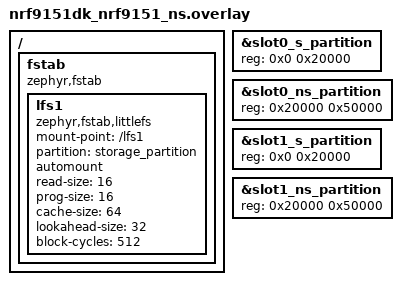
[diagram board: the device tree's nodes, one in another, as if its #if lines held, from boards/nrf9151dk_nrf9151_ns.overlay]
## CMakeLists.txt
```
# SPDX-License-Identifier: Apache-2.0

cmake_minimum_required(VERSION 3.13.1)

if(DEFINED ENV{MEMFAULT_ZEPHYR_EXTRA_MODULE_INCLUDE})
  list(APPEND ZEPHYR_EXTRA_MODULES $ENV{ZEPHYR_BASE}/../modules/memfault-firmware-sdk/ports)
endif()

# We need the nRF Connect SDK version before loading Zephyr, to dynamically
# select Kconfig overlays based on version- not something that can be achieved
# with Zephyr today.
#
# Note: previously this was done with 'find_package(Ncs)', but as of sdk-nrf
# commit 40f7487d3a ("cmake: adopt VERSION to common VERSION file format"),
# NcsConfig.cmake requires ZEPHYR_BASE to be set, which is not available before
# 'find_package(Zephyr)'. Instead, read the version directly from the VERSION
# file, supporting both formats:
# - nRF Connect SDK <= v3.3.0: single line, "<major>.<minor>.<patch>[-extra]"
# - newer: Zephyr-style "VERSION_MAJOR = <major>" etc. key-value lines
set(NCS_VERSION_FILE "$ENV{ZEPHYR_BASE}/../nrf/VERSION")
if(EXISTS "${NCS_VERSION_FILE}")
  file(READ "${NCS_VERSION_FILE}" ncs_version_content)
  if(ncs_version_content MATCHES "VERSION_MAJOR *= *([0-9]+)")
    set(NCS_VERSION_MAJOR ${CMAKE_MATCH_1})
    string(REGEX MATCH "VERSION_MINOR *= *([0-9]+)" _ "${ncs_version_content}")
    set(NCS_VERSION_MINOR ${CMAKE_MATCH_1})
    string(REGEX MATCH "PATCHLEVEL *= *([0-9]+)" _ "${ncs_version_content}")
    set(NCS_VERSION_PATCH ${CMAKE_MATCH_1})
  elseif(ncs_version_content MATCHES "([0-9]+)\\.([0-9]+)\\.([0-9]+)")
    set(NCS_VERSION_MAJOR ${CMAKE_MATCH_1})
    set(NCS_VERSION_MINOR ${CMAKE_MATCH_2})
    set(NCS_VERSION_PATCH ${CMAKE_MATCH_3})
  endif()
endif()

# Confirm NCS_VERSION_MAJOR is defined
if (NOT DEFINED NCS_VERSION_MAJOR)
  message(FATAL_ERROR "NCS Version not found, please contact Memfault support!")
endif()

# Below we conditionally set Kconfig variables via overlays based on nRF Connect SDK version
# (since setting non-existent variables result in a build time error which
# would break compiling older builds)

if (${NCS_VERSION_MAJOR}.${NCS_VERSION_MINOR}.${NCS_VERSION_PATCH} VERSION_GREATER_EQUAL 2.9.99)
set(OVERLAY_CONFIG "${OVERLAY_CONFIG};overlays/ncs-main.conf")
endif()

if (${NCS_VERSION_MAJOR}.${NCS_VERSION_MINOR}.${NCS_VERSION_PATCH} VERSION_GREATER_EQUAL 3.3.0)
set(OVERLAY_CONFIG "${OVERLAY_CONFIG};overlays/ncs-v3.3.0.conf")
endif()

if (${NCS_VERSION_MAJOR}.${NCS_VERSION_MINOR}.${NCS_VERSION_PATCH} VERSION_LESS 2.9.99)
set(OVERLAY_CONFIG "${OVERLAY_CONFIG};overlays/ncs-pre-v2.9.99.conf")
endif()

if (${NCS_VERSION_MAJOR}.${NCS_VERSION_MINOR}.${NCS_VERSION_PATCH} VERSION_LESS 2.8.0)
set(OVERLAY_CONFIG "${OVERLAY_CONFIG};overlays/ncs-pre-v2.8.0.conf")
endif()

if (${NCS_VERSION_MAJOR}.${NCS_VERSION_MINOR}.${NCS_VERSION_PATCH} VERSION_LESS 2.2.99)
set(OVERLAY_CONFIG "${OVERLAY_CONFIG};overlays/ncs-pre-v2.2.99.conf")
endif()

if (${NCS_VERSION_MAJOR}.${NCS_VERSION_MINOR}.${NCS_VERSION_PATCH} VERSION_LESS 2.4.0)
set(OVERLAY_CONFIG "${OVERLAY_CONFIG};overlays/ncs-pre-v2.4.0.conf")
endif()

if (${NCS_VERSION_MAJOR}.${NCS_VERSION_MINOR}.${NCS_VERSION_PATCH} VERSION_LESS 2.0.0)
set(OVERLAY_CONFIG "${OVERLAY_CONFIG};overlays/ncs-pre-v2.0.0.conf")
endif()

# NCS >= 3.4.0 disables Partition Manager by default, which changes the
# secure/non-secure flash split on nRF91-family DK boards (see the
# NCS_PARTITION_MANAGER_REMOVED guarded blocks in boards/*.overlay for
# details). BOARD isn't known yet at this point in a sysbuild configure, so
# this can't be gated by board here - instead it's passed down as a
# devicetree preprocessor define, and the affected board overlay files guard
# their partition-resizing nodes on it.
if (${NCS_VERSION_MAJOR}.${NCS_VERSION_MINOR}.${NCS_VERSION_PATCH} VERSION_GREATER_EQUAL 3.4.0)
set(DTS_EXTRA_CPPFLAGS "${DTS_EXTRA_CPPFLAGS};-DNCS_PARTITION_MANAGER_REMOVED")
endif()

find_package(Zephyr HINTS $ENV{ZEPHYR_BASE})
project(hello_world)

target_sources(app PRIVATE src/main.c)
target_sources(app PRIVATE src/watchdog.c)
zephyr_include_directories(config)
```

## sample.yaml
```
sample:
  description: Memfault SDK example integration built on top of Hello
    World Sample App with the nRF Connect SDK
  name: Memfault Demo App
```

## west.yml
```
manifest:
  projects:
    - name: nrf
      url: https://github.com/nrfconnect/sdk-nrf
      revision: v3.4.1
      import:
        path-blocklist: modules/lib/memfault-firmware-sdk
        name-blocklist:
          # unused, save the download
          - matter
    - name: memfault-firmware-sdk
      url: https://github.com/memfault/memfault-firmware-sdk
      path: modules/lib/memfault-firmware-sdk
      revision: master
  self:
    path: memfault_demo_app
    import: submanifests
```

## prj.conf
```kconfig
# project specific configuration settings

# Note: See the overlays directory for additional Kconfig variables settings as not all variables can be
# set in a single prj.conf for backward compatibility with older versions of the nRF Connect SDK /
# Zephyr

CONFIG_NETWORKING=y
CONFIG_NET_SOCKETS=y
CONFIG_NET_NATIVE=n

CONFIG_HEAP_MEM_POOL_SIZE=4096
CONFIG_MAIN_STACK_SIZE=4096
CONFIG_SYSTEM_WORKQUEUE_STACK_SIZE=2048
CONFIG_MODEM_KEY_MGMT=y
CONFIG_LTE_LINK_CONTROL=y
CONFIG_NRF_MODEM_LIB=y
CONFIG_MODEM_INFO=y
CONFIG_AT_SHELL=y
# Note: CONFIG_AT_SHELL_CMD_MODE is set in overlays/ncs-v3.3.0.conf for NCS >= 3.3.0

CONFIG_SHELL=y
CONFIG_SHELL_LOG_BACKEND=n

# Make it possible to send AT commands ending with a "?"
#  https://developer.nordicsemi.com/nRF_Connect_SDK/doc/2.4.2/nrf/libraries/modem/at_shell.html
CONFIG_SHELL_WILDCARD=y

CONFIG_NET_LOG=y

CONFIG_NET_SOCKETS_OFFLOAD=y

CONFIG_MEMFAULT=y
CONFIG_MEMFAULT_NCS_DEVICE_ID_RUNTIME=y

# Note: Can optionally be changed to =y to implement
# a custom event handler for FOTA events
# CONFIG_MEMFAULT_FOTA_DOWNLOAD_CALLBACK_CUSTOM=n

# Enable to demo custom reboot reason capture
CONFIG_MEMFAULT_REBOOT_REASON_CUSTOM_ENABLE=y

# Required for logging backends to work as expected
CONFIG_LOG=y
CONFIG_LOG_BACKEND_UART=y

# Disable logging of printk, to improve 'mflt export' performance under deferred
# logging mode.
CONFIG_LOG_PRINTK=n

# Enable Bootloader so OTA updates can be performed
CONFIG_BOOTLOADER_MCUBOOT=y
CONFIG_MCUBOOT_IMG_MANAGER=y

# The subsystems we need so OTA payloads can be written to
# flash and updated by MCUBoot
CONFIG_DFU_TARGET=y
CONFIG_DFU_TARGET_MCUBOOT=y
CONFIG_IMG_MANAGER=y
CONFIG_FLASH=y
CONFIG_FLASH_MAP=y
CONFIG_STREAM_FLASH=y
CONFIG_IMG_ERASE_PROGRESSIVELY=y

# For Memfault FOTA, we will use the FOTA_DOWNLOAD API's
# from the nRF Connect SDK which depends on the DOWNLOAD_CLIENT
CONFIG_FOTA_DOWNLOAD=y

# Enable Modem FOTA via Memfault
# CONFIG_MEMFAULT_FOTA_MODEM_UPDATE=y
# Optional, only if modem firmware is hosted in a separate, dedicated project:
# CONFIG_MEMFAULT_FOTA_MODEM_PROJECT_KEY="fill_in_modem_fota_project_key"

# Enable printing of file download progress to console
CONFIG_FOTA_DOWNLOAD_PROGRESS_EVT=y

CONFIG_WATCHDOG=y

# Enable Zephyr runtime asserts
CONFIG_ASSERT=y

# Enable littlefs on internal flash, to demo the file system utilization metric
CONFIG_FILE_SYSTEM=y
CONFIG_FILE_SYSTEM_LITTLEFS=y
CONFIG_FILE_SYSTEM_SHELL=y

# Enable Nordic datetime library, which will get network time from the modem
CONFIG_DATE_TIME=y
```

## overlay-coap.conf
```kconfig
# Overlay for selecting CoAP for connecting to Memfault.
# Requires NCS >=2.8.0.

# Enable CoAP, disable HTTP
CONFIG_MEMFAULT_USE_NRF_CLOUD_COAP=y
CONFIG_MEMFAULT_HTTP_ENABLE=n

# Enable Modem FOTA updates
# Uses the main project by default. To use a separate, dedicated modem project, set its key via
# CLI (mflt set_modem_project_key) or via Kconfig (CONFIG_MEMFAULT_FOTA_MODEM_PROJECT_KEY)
CONFIG_MEMFAULT_FOTA_MODEM_UPDATE=y

# nRF Cloud CoAP (required for Memfault CoAP uploads)
CONFIG_NRF_CLOUD=y
CONFIG_NRF_CLOUD_COAP=y
# Use the modem's internal UUID as the nRF Cloud client ID (for JWT auth)
CONFIG_NRF_CLOUD_CLIENT_ID_SRC_INTERNAL_UUID=y
CONFIG_MODEM_JWT=y

# Required to be able to use the nRF Cloud CoAP connection for FOTA image downloads
CONFIG_NRF_CLOUD_FOTA=y
CONFIG_DOWNLOADER_TRANSPORT_COAP=y

# Ensure Memfault device id matches nRF Cloud client id
CONFIG_MEMFAULT_NCS_DEVICE_ID_HW_ID=y
CONFIG_HW_ID_LIBRARY_SOURCE_UUID=y

# CoAP client (needs more stack and heap than HTTP)
CONFIG_COAP_CLIENT_BLOCK_SIZE=1024
CONFIG_COAP_CLIENT_STACK_SIZE=6144
CONFIG_COAP_CLIENT_THREAD_PRIORITY=0
CONFIG_COAP_CLIENT_MAX_PATH_LENGTH=400
CONFIG_AT_MONITOR_HEAP_SIZE=512
CONFIG_SHELL_STACK_SIZE=2560

# Required for streaming large FOTA images from nRF Cloud over CoAP
CONFIG_HEAP_MEM_POOL_SIZE=12288

CONFIG_COAP_EXTENDED_OPTIONS_LEN_VALUE=192
CONFIG_NRF_CLOUD_COAP_MAX_USER_OPTIONS=2
CONFIG_COAP_CLIENT_MAX_EXTRA_OPTIONS=3

# nRF Cloud shadow updates use cJSON which serializes float/double values via
# snprintf("%g", ...). Without this, floats render as "*float*" in the JSON
# string, causing nRF Cloud to reject shadow PATCHes with "Malformed JSON".
CONFIG_CBPRINTF_FP_SUPPORT=y
```

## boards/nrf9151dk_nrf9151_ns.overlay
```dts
/* Device Tree overlay to enable auto-mounting littlefs in an internal
   partition, via the Nordic Partition Manager system */

/ {
	fstab {
		compatible = "zephyr,fstab";
		lfs1: lfs1 {
			compatible = "zephyr,fstab,littlefs";
			mount-point = "/lfs1";
			partition = <&storage_partition>;
			automount;
			read-size = <16>;
			prog-size = <16>;
			cache-size = <64>;
			lookahead-size = <32>;
			block-cycles = <512>;
		};
	};
};

#if defined(NCS_PARTITION_MANAGER_REMOVED)
/*
 * NCS >= 3.4.0 disables Partition Manager by default, falling back to this
 * board's static devicetree partition layout, which splits the primary and
 * secondary image areas into a 256 KB secure (TF-M) / 192 KB non-secure
 * region. When Partition Manager was in control it sized that split
 * dynamically based on what TF-M and this app actually needed.
 * For the non-secure image, it chose 320 KB, which gives it plenty of headroom. Shrink the secure region
 * and grow the non-secure one to match what Partition Manager used to
 * allocate, so the app still fits.
 */
&slot0_s_partition {
	reg = <0x0 0x20000>;
};

&slot0_ns_partition {
	reg = <0x20000 0x50000>;
};

&slot1_s_partition {
	reg = <0x0 0x20000>;
};

&slot1_ns_partition {
	reg = <0x20000 0x50000>;
};
#endif
```

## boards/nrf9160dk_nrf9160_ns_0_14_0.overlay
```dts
/* Device Tree overlay to enable auto-mounting littlefs in an internal
   partition, via the Nordic Partition Manager system */

/ {
	fstab {
		compatible = "zephyr,fstab";
		lfs1: lfs1 {
			compatible = "zephyr,fstab,littlefs";
			mount-point = "/lfs1";
			partition = <&storage_partition>;
			automount;
			read-size = <16>;
			prog-size = <16>;
			cache-size = <64>;
			lookahead-size = <32>;
			block-cycles = <512>;
		};
	};
};

#if defined(NCS_PARTITION_MANAGER_REMOVED)
/*
 * NCS >= 3.4.0 disables Partition Manager by default, falling back to this
 * board's static devicetree partition layout, which splits the primary and
 * secondary image areas into a 256 KB secure (TF-M) / 192 KB non-secure
 * region. When Partition Manager was in control it sized that split
 * dynamically based on what TF-M and this app actually needed, leaving this
 * app's non-secure image comfortably under 320 KB. Shrink the secure region
 * and grow the non-secure one to match what Partition Manager used to
 * allocate, so the app still fits.
 */
&slot0_s_partition {
	reg = <0x0 0x20000>;
};

&slot0_ns_partition {
	reg = <0x20000 0x50000>;
};

&slot1_s_partition {
	reg = <0x0 0x20000>;
};

&slot1_ns_partition {
	reg = <0x20000 0x50000>;
};
#endif
```

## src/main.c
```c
//! @file
//!
//! Copyright (c) Memfault, Inc.
//! See LICENSE for details

// clang-format off
#include "memfault/ports/zephyr/include_compatibility.h"

#include MEMFAULT_ZEPHYR_INCLUDE(device.h)
#include MEMFAULT_ZEPHYR_INCLUDE(kernel.h)
#include MEMFAULT_ZEPHYR_INCLUDE(sys/printk.h)
#include MEMFAULT_ZEPHYR_INCLUDE(shell/shell.h)
#include <string.h>
#include <stdio.h>

#include "memfault/components.h"
#include "memfault/ports/zephyr/thread_metrics.h"
#include "memfault/ports/zephyr/http.h"
#include "memfault/ports/ncs/version.h"
#include "memfault/ports/ncs/date_time_callback.h"
#include "memfault_demo_app.h"

#if defined(CONFIG_AT_SHELL_CMD_MODE)
#include <modem/at_shell.h>
#endif

#include <modem/modem_info.h>
#ifdef CONFIG_LTE_LINK_CONTROL
  #include <modem/lte_lc.h>
#else
  #include <nrf_modem_at.h>
#endif

#if defined(CONFIG_NRF_CLOUD_COAP)
#include <date_time.h>
#include <net/nrf_cloud_coap.h>

static K_SEM_DEFINE(s_date_time_ready, 0, 1);

static void prv_date_time_evt_handler(const struct date_time_evt *evt) {
#if defined(CONFIG_MEMFAULT_SYSTEM_TIME_SOURCE_DATETIME)
  // Forward event to Memfault's date/time callback handler, which will update
  // the system time used for timestamping events and coredumps
  memfault_zephyr_date_time_evt_handler(evt);
#endif

  // Only signal that date/time is ready on successful time obtain events
  if ((evt != NULL) && (evt->type != DATE_TIME_NOT_OBTAINED)) {
    k_sem_give(&s_date_time_ready);
  }
}
#endif

MEMFAULT_METRICS_DEFINE_THREAD_METRICS(
{
  .thread_name = "idle",
  .stack_usage_metric_key = MEMFAULT_METRICS_KEY(memory_idle_pct_max),
},
{
  .thread_name = "sysworkq",
  .stack_usage_metric_key = MEMFAULT_METRICS_KEY(memory_sysworkq_pct_max),
},
{
  .thread_name = "mflt_upload",
  .stack_usage_metric_key = MEMFAULT_METRICS_KEY(memory_mflt_upload_pct_max),
},
{
  .thread_name = "🐶 wdt",
  .stack_usage_metric_key = MEMFAULT_METRICS_KEY(memory_wdt_pct_max),
},
{
  .thread_name = "shell_uart",
  .stack_usage_metric_key = MEMFAULT_METRICS_KEY(memory_shell_uart_pct_max),
}
);

#if !MEMFAULT_NCS_VERSION_GT(2, 3)
/* nRF Connect SDK >= 1.9.2 || <= 2.3 */
#include "memfault_ncs.h"
#include <modem/nrf_modem_lib.h>
static int prv_init_modem_lib(void) {
  return nrf_modem_lib_init(NORMAL_MODE);
}
#else /* nRF Connect SDK >= 2.4 */
#include "memfault_ncs.h"
#include <modem/nrf_modem_lib.h>
static int prv_init_modem_lib(void) {
  return nrf_modem_lib_init();
}
#endif

#include MEMFAULT_ZEPHYR_INCLUDE(logging/log.h)
LOG_MODULE_REGISTER(mflt_demo_app, LOG_LEVEL_INF);

#if CONFIG_DFU_TARGET_MCUBOOT
#include MEMFAULT_ZEPHYR_INCLUDE(dfu/mcuboot.h)
#endif

#if defined(CONFIG_MEMFAULT_FOTA_COMPONENTS)
#include "memfault/nrfconnect_port/fota_component.h"
#endif
// clang-format on

#if defined(CONFIG_MEMFAULT_FOTA_COMPONENTS)
// Phony component for testing, e.g. with "mflt get_latest_url example-component"
static int prv_example_component_version_get(char *buf, size_t buf_len) {
  snprintf(buf, buf_len, "1.0.0");
  return 0;
}

MEMFAULT_FOTA_COMPONENT_DEFINE(example_component, "example-component",
                               prv_example_component_version_get,
                               kMemfaultFotaComponentInstall_None);
#endif

#if defined(CONFIG_MEMFAULT_NCS_DEVICE_ID_RUNTIME)
  // Since the example app manages when the modem starts/stops, we manually configure the device
  // serial even when using nRF Connect SDKs including the Memfault integration (by using
  // CONFIG_MEMFAULT_NCS_DEVICE_ID_RUNTIME)
  #define IMEI_LEN 15
static char s_device_serial[IMEI_LEN + 1 /* '\0' */] = "unknown";

static int prv_get_imei(char *buf, size_t buf_len) {
  // use the cached modem info to fetch the IMEI
  int err = modem_info_init();
  if (err != 0) {
    printk("Modem info Init error: %d\n", err);
  } else {
    modem_info_string_get(MODEM_INFO_IMEI, buf, buf_len);
  }
  return err;
}

static void prv_init_device_info(void) {
  // we'll use the IMEI as the device serial
  char modem_info[MODEM_INFO_MAX_RESPONSE_SIZE];

  int ret = prv_get_imei(modem_info, sizeof(modem_info));
  if (ret != 0) {
    printk("Failed to get IMEI\n\r");
  } else {
    modem_info[IMEI_LEN] = '\0';
    strcpy(s_device_serial, modem_info);
    printk("IMEI: %s\n", s_device_serial);
  }

  // register the device id with memfault port so it is used for reporting
  memfault_ncs_device_id_set(s_device_serial, IMEI_LEN);
}
#endif

#if defined(CONFIG_AT_SHELL_CMD_MODE)
K_THREAD_STACK_DEFINE(my_work_q_stack, 2048);
static struct k_work_q my_work_q;

static void prv_at_shell_init(void) {
  k_work_queue_start(&my_work_q, my_work_q_stack, K_THREAD_STACK_SIZEOF(my_work_q_stack),
                     K_PRIO_PREEMPT(7), NULL);

  struct at_shell_config at_cfg = {
    .at_cmd_mode_work_q = &my_work_q,
  };
  at_shell_init(&at_cfg);
}
#endif  // CONFIG_AT_SHELL_CMD_MODE

int main(void) {
  printk("Memfault Demo App Started!\n");

  memfault_demo_app_watchdog_boot();

#if defined(CONFIG_AT_SHELL_CMD_MODE)
  prv_at_shell_init();
#endif

#if CONFIG_DFU_TARGET_MCUBOOT
  if (!boot_is_img_confirmed()) {
    // Mark the ota image as installed so we don't revert
    printk("Confirming OTA update\n");
    boot_write_img_confirmed();
  }
#endif

  int err = prv_init_modem_lib();
  if (err) {
    printk("Failed to initialize modem!");
    goto cleanup;
  }

#if defined(CONFIG_MEMFAULT_NCS_DEVICE_ID_RUNTIME)
  // requires AT modem interface to be up
  prv_init_device_info();
#endif

#if defined(CONFIG_MEMFAULT_HTTP_ENABLE) && \
  !defined(CONFIG_MEMFAULT_ROOT_CERT_INSTALL_ON_MODEM_LIB_INIT)
  // Note: We must provision certs prior to connecting to the LTE network
  // in order to use them
  err = memfault_zephyr_port_install_root_certs();
  if (err) {
    goto cleanup;
  }
#endif

#if defined(CONFIG_MEMFAULT_HTTP_SOCKET_DISPATCH)
  // Set the network interface name to use for Memfault HTTP uploads
  err = memfault_zephyr_port_http_set_interface_name("net0");
  if (err) {
    printk("Failed to set Memfault HTTP network interface name, err %d\n", err);
    goto cleanup;
  }
#endif

#if defined(CONFIG_NRF_CLOUD_COAP)
  // Register early so we don't miss the time-update event after LTE connects.
  // JWT authentication (used by nRF Cloud CoAP) requires a valid timestamp.
  date_time_register_handler(prv_date_time_evt_handler);
#endif

  LOG_INF("Waiting for network...");
#ifdef CONFIG_LTE_LINK_CONTROL
  // lte_lc_init_and_connect is deprecated in NCS 2.6
  #if MEMFAULT_NCS_VERSION_GT(2, 5)
  err = lte_lc_connect();
  #else
  err = lte_lc_init_and_connect();
  #endif
  if (err) {
    LOG_ERR("Failed to connect to the LTE network, err %d", err);
    goto cleanup;
  }
  LOG_INF("OK (connected)");
#else
  // Without LTE_LINK_CONTROL, put modem in normal mode via AT command.
  // Connection progress is tracked asynchronously via +CEREG notifications.
  err = nrf_modem_at_printf("AT+CFUN=1") ? -EIO : 0;
  if (err) {
    LOG_ERR("Failed to set modem to normal mode, err %d", err);
    goto cleanup;
  }
  LOG_INF("Modem activated (connecting asynchronously)");
#endif

#if defined(CONFIG_NRF_CLOUD_COAP)
  // Wait for the date/time library to sync from the network (up to 10 minutes).
  // nrf_cloud_coap_connect() uses a JWT signed with the current time; connecting
  // before the clock is set will result in an authentication failure.
  printk("Waiting for date/time sync...\n");
  k_sem_take(&s_date_time_ready, K_MINUTES(10));
  if (!date_time_is_valid()) {
    printk("Warning: date/time not yet valid, CoAP connect may fail\n");
  }

  err = nrf_cloud_coap_init();
  if (err) {
    printk("Failed to initialize nRF Cloud CoAP client, err %d\n", err);
    goto cleanup;
  }

  err = nrf_cloud_coap_connect(NULL);
  if (err) {
    printk("Failed to connect to nRF Cloud via CoAP, err %d\n", err);
    goto cleanup;
  }
  printk("Connected to nRF Cloud via CoAP\n");
#endif

cleanup:
  return err;
}

static int prv_reboot_custom(const struct shell *shell, size_t argc, char **argv) {
  if (argc != 2) {
    shell_print(shell, "Usage: app reboot_custom <expected|unexpected>");
    return -1;
  }
  if (strcmp(argv[1], "expected") == 0) {
    MEMFAULT_REBOOT_MARK_RESET_IMMINENT_CUSTOM(CustomExpectedReboot);
  } else if (strcmp(argv[1], "unexpected") == 0) {
    MEMFAULT_REBOOT_MARK_RESET_IMMINENT_CUSTOM(CustomUnexpectedReboot);
  } else {
    shell_print(shell, "Invalid argument: %s", argv[1]);
    return -1;
  }

  shell_print(shell, "Rebooting with custom reason...");

  // Allow the shell output buffer to be flushed before the reboot
  k_sleep(K_MSEC(100));
  memfault_platform_reboot();
  return 0;  // should be unreachable
}

#if defined(CONFIG_MEMFAULT_HTTP_SOCKET_DISPATCH)
static int prv_set_net_iface(const struct shell *shell, size_t argc, char **argv) {
  if (argc != 2) {
    shell_print(shell, "Usage: app set_net_iface <if_name>");
    return -1;
  }
  const char *if_name = argv[1];
  int err = memfault_zephyr_port_http_set_interface_name(if_name);
  if (err) {
    shell_print(shell, "Failed to set Memfault HTTP network interface name, err %d", err);
    return err;
  }
  shell_print(shell, "Set Memfault HTTP network interface name to: %s", if_name);
  return 0;
}
#endif

SHELL_STATIC_SUBCMD_SET_CREATE(
  sub_app_cmds, SHELL_CMD(reboot_custom, NULL, "test custom reboot", prv_reboot_custom),
#if defined(CONFIG_MEMFAULT_HTTP_SOCKET_DISPATCH)
  SHELL_CMD(set_net_iface, NULL, "set net iface name", prv_set_net_iface),
#endif
  SHELL_SUBCMD_SET_END /* Array terminated. */
);

SHELL_CMD_REGISTER(app, &sub_app_cmds, "Memfault Demo App Test Commands", NULL);
```

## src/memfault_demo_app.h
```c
#pragma once

//! @file
//!
//! Copyright (c) Memfault, Inc.
//! See LICENSE for details

//! Start watchdog subsystem for demo application
void memfault_demo_app_watchdog_boot(void);

//! Reset watchdog timeout for application
void memfault_demo_app_watchdog_feed(void);
```

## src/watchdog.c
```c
//! @file
//!
//! Copyright (c) Memfault, Inc.
//! See LICENSE for details
//!
//! Example configuration of Zephyr hardware watchdog with Memfault software watchdog
//! port such that a coredump is captured ahead of the hardware watchdog firing

// clang-format off
#include "memfault/ports/watchdog.h"

#include "memfault/ports/zephyr/include_compatibility.h"

#include MEMFAULT_ZEPHYR_INCLUDE(device.h)
#include MEMFAULT_ZEPHYR_INCLUDE(drivers/watchdog.h)
#include MEMFAULT_ZEPHYR_INCLUDE(kernel.h)

#include "memfault/components.h"
#include "memfault/ports/zephyr/version.h"
// clang-format on

//! Note: The timeout must be large enough to give us enough time to capture a coredump
//! before the system resets
#define MEMFAULT_WATCHDOG_HW_TIMEOUT_SECS (MEMFAULT_WATCHDOG_SW_TIMEOUT_SECS + 10)

#define WDT_MAX_WINDOW (MEMFAULT_WATCHDOG_HW_TIMEOUT_SECS * 1000)

#define WATCHDOG_TASK_STACK_SIZE 512
K_THREAD_STACK_DEFINE(s_wdt_task_stack_area, WATCHDOG_TASK_STACK_SIZE);
struct k_thread wdt_thread;

#if MEMFAULT_ZEPHYR_VERSION_GT(3, 1)
// Between Zephyr 3.1 and 3.2, "label" properties in DTS started to get phased out:
//   https://github.com/zephyrproject-rtos/zephyr/pull/48360
//
// This breaks support for accessing device tree information via device_get_binding / DT_LABEL
// properties. The new preferred approach is accessing resources via the DEVICE_DT_GET macro
static const struct device *s_wdt = DEVICE_DT_GET(DT_NODELABEL(wdt));

#else
static const struct device *s_wdt = NULL;
#endif

//! Watchdog device tree name changed in NCS v2.0.0 :
//! https://github.com/nrfconnect/sdk-zephyr/blob/12ee4d5f4b99acef542ce3977cb9078fcbb36d82/dts/arm/nordic/nrf9160_common.dtsi#L368
//! Pick the one that's available in the current SDK version.
#if DT_HAS_COMPAT_STATUS_OKAY(nordic_nrf_wdt)
  #define WDT_NODE_NAME nordic_nrf_wdt
#elif DT_HAS_COMPAT_STATUS_OKAY(nordic_nrf_watchdog)
  #define WDT_NODE_NAME nordic_nrf_watchdog
#else
  #error "No compatible watchdog instance for this configuration!"
#endif

#define WDT_NODE DT_INST(0, WDT_NODE_NAME)
#define WDT_DEV_NAME DT_LABEL(WDT_NODE)

static int s_wdt_channel_id = -1;

void memfault_demo_app_watchdog_feed(void) {
  if ((s_wdt == NULL) || (s_wdt_channel_id < 0)) {
    return;
  }

  wdt_feed(s_wdt, s_wdt_channel_id);
  memfault_software_watchdog_feed();
}

//! A basic watchdog implementation
//!
//! Once Zephyr has a Software & Task watchdog in place, the example will be updated to make use of
//! that For more info about watchdog setup in general, see https://mflt.io/root-cause-watchdogs
static void prv_wdt_task(void *arg1, void *arg2, void *arg3) {
  while (1) {
    k_sleep(K_SECONDS(1));

    memfault_demo_app_watchdog_feed();
  }
}

void memfault_demo_app_watchdog_boot(void) {
  MEMFAULT_LOG_DEBUG("Initializing WDT Subsystem");

#if MEMFAULT_ZEPHYR_VERSION_GT(3, 1)
  if (!device_is_ready(s_wdt)) {
    printk("Watchdog device not ready");
    return;
  }
#else  // Zephyr <= 3.1
  s_wdt = device_get_binding(WDT_DEV_NAME);
  if (s_wdt == NULL) {
    printk("No WDT device available\n");
    return;
  }
#endif

  struct wdt_timeout_cfg wdt_config = {
    /* Reset SoC when watchdog timer expires. */
    .flags = WDT_FLAG_RESET_SOC,

    /* Expire watchdog after max window */
    .window.min = 0U,
    .window.max = WDT_MAX_WINDOW,
  };

  s_wdt_channel_id = wdt_install_timeout(s_wdt, &wdt_config);
  if (s_wdt_channel_id < 0) {
    MEMFAULT_LOG_ERROR("Watchdog install error, rv=%d", s_wdt_channel_id);
    return;
  }

  const uint8_t options = WDT_OPT_PAUSE_HALTED_BY_DBG;
  int err = wdt_setup(s_wdt, options);
  if (err < 0) {
    MEMFAULT_LOG_ERROR("Watchdog setup error, rv=%d", err);
    return;
  }

  // start a low priority task that feeds the watchdog.
  // We make it the lowest priority so a hot loop in any task above will
  // cause the watchdog to not be fed
  memfault_software_watchdog_enable();
  k_thread_create(&wdt_thread, s_wdt_task_stack_area, K_THREAD_STACK_SIZEOF(s_wdt_task_stack_area),
                  prv_wdt_task, NULL, NULL, NULL, K_LOWEST_APPLICATION_THREAD_PRIO, 0, K_NO_WAIT);
  k_thread_name_set(&wdt_thread, "🐶 wdt");
}
```
